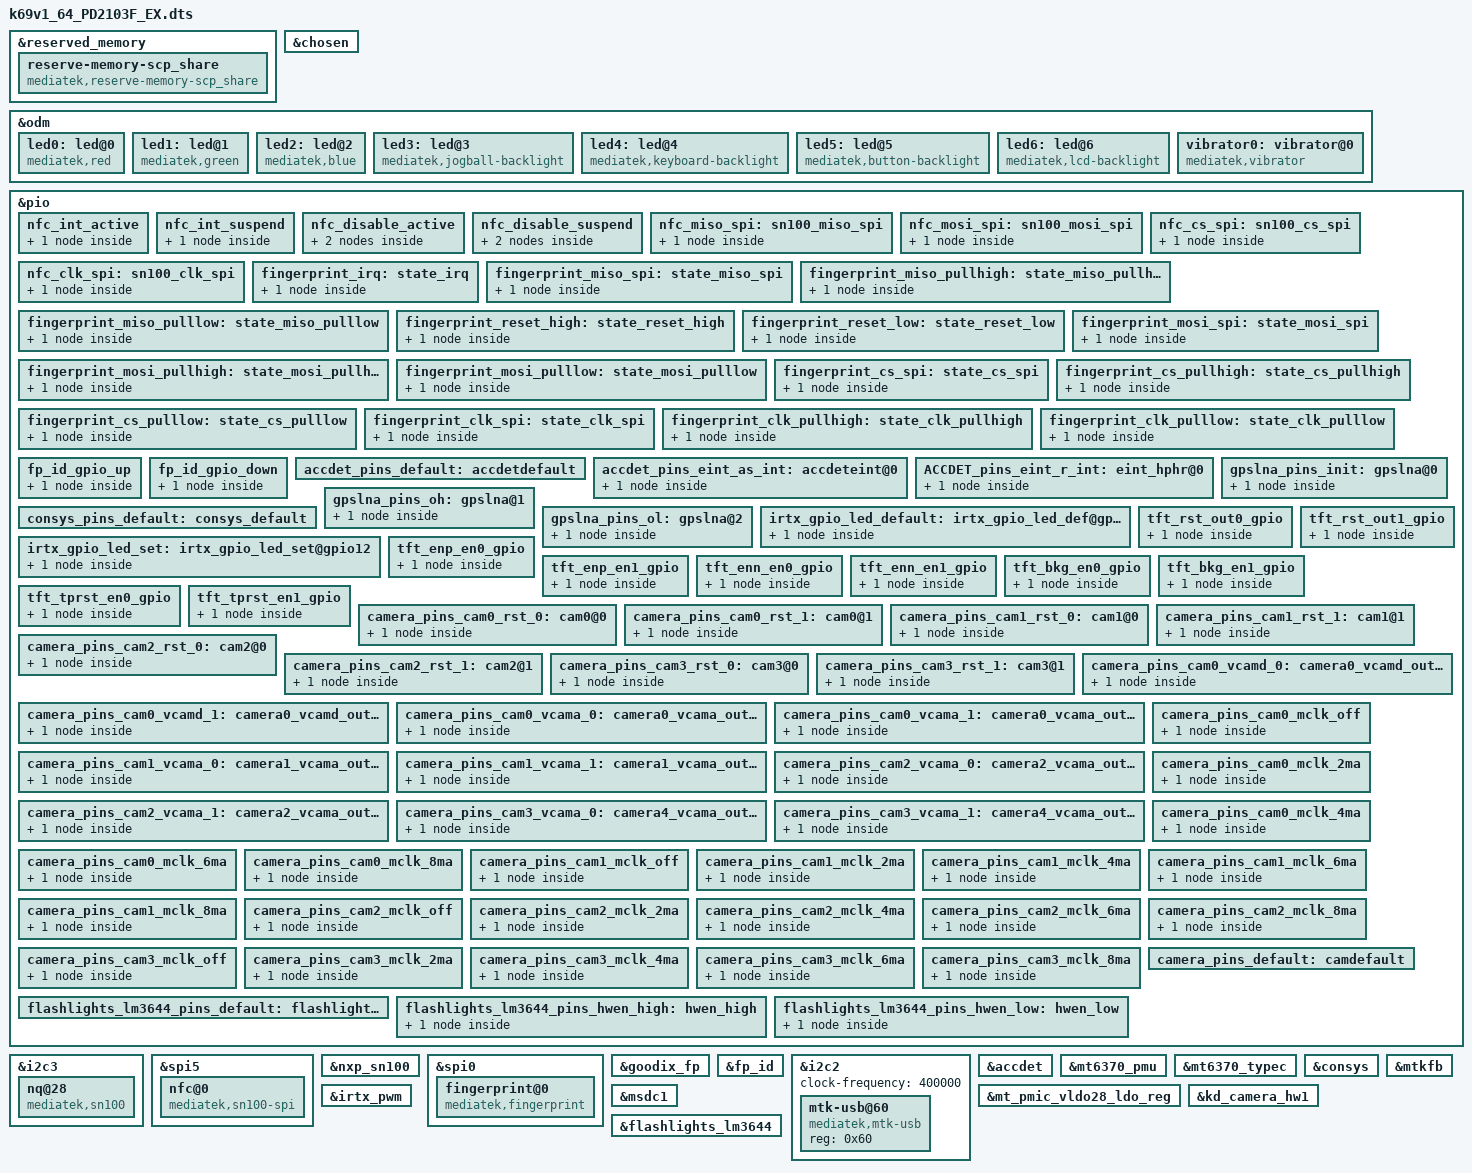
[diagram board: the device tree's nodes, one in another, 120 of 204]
/*
 * Copyright (C) 2019 MediaTek Inc.
 *
 * This program is free software; you can redistribute it and/or modify
 * it under the terms of the GNU General Public License version 2 as
 * published by the Free Software Foundation.
 *
 * This program is distributed in the hope that it will be useful,
 * but WITHOUT ANY WARRANTY; without even the implied warranty of
 * MERCHANTABILITY or FITNESS FOR A PARTICULAR PURPOSE.
 * See http://www.gnu.org/licenses/gpl-2.0.html for more details.
 */

/dts-v1/;
/plugin/;
#include <generated/autoconf.h>
#include <dt-bindings/interrupt-controller/irq.h>
#include <dt-bindings/interrupt-controller/arm-gic.h>
#include <dt-bindings/pinctrl/mt6768-pinfunc.h>

&reserved_memory {
	reserve-memory-scp_share {
		compatible = "mediatek,reserve-memory-scp_share";
		no-map;
		size = <0 0x00d00000>;
		alignment = <0 0x1000000>;
		alloc-ranges = <0 0x40000000 0 0x50000000>;
	};
};

/* chosen */
&chosen {

	atag,videolfb-fb_base_l = <0x7e605000>;
	atag,videolfb-fb_base_h = <0x0>;
	atag,videolfb-islcmfound = <1>;
	atag,videolfb-islcm_inited = <0>;
	atag,videolfb-fps= <6000>;
	atag,videolfb-vramSize= <0x017e8000>;
	atag,videolfb-lcmname=
		"hx83112b_fhdp_dsi_cmd_auo_rt5081_drv";
	default-backlight-level = <1600>;
	atag,videolfb-project-name= "pd2103";
	atag,vivo-dsi-panel-type = "tft";
	bias-ic-use-i2c = <0>;
	bl-ic-use-i2c = <0>;
};

&odm {
	led0:led@0 {
		compatible = "mediatek,red";
		led_mode = <0>;
		data = <1>;
		pwm_config = <0 0 0 0 0>;
	};
	led1:led@1 {
		compatible = "mediatek,green";
		led_mode = <0>;
		data = <1>;
		pwm_config = <0 0 0 0 0>;
	};
	led2:led@2 {
		compatible = "mediatek,blue";
		led_mode = <0>;
		data = <1>;
		pwm_config = <0 0 0 0 0>;
	};
	led3:led@3 {
		compatible = "mediatek,jogball-backlight";
		led_mode = <0>;
		data = <1>;
		pwm_config = <0 0 0 0 0>;
	};
	led4:led@4 {
		compatible = "mediatek,keyboard-backlight";
		led_mode = <0>;
		data = <1>;
		pwm_config = <0 0 0 0 0>;
	};
	led5:led@5 {
		compatible = "mediatek,button-backlight";
		led_mode = <0>;
		data = <1>;
		pwm_config = <0 0 0 0 0>;
	};
	led6:led@6 {
		compatible = "mediatek,lcd-backlight";
		led_mode = <4>;
		data = <1>;
		pwm_config = <0 3 0 0 0>;
	};
	vibrator0:vibrator@0 {
		compatible = "mediatek,vibrator";
		vib_timer = <25>;
		vib_limit = <9>;
		vib_vol= <11>;
	};
};

/* NFC GPIO standardization begin*/
&pio {
	nfc_int_active: nfc_int_active {
		pins_cmd0_dat {
			pinmux = <PINMUX_GPIO9__FUNC_GPIO9>;
			bias-pull-up;
		};
	};
	nfc_int_suspend: nfc_int_suspend {
		pins_cmd0_dat {
			pinmux = <PINMUX_GPIO9__FUNC_GPIO9>;
			bias-pull-up;
		};
	};
	nfc_disable_active: nfc_disable_active {
		pins_cmd0_dat {
			pinmux = <PINMUX_GPIO17__FUNC_GPIO17>;
			bias-pull-up;
		};
		pins_cmd1_dat {
			pinmux = <PINMUX_GPIO19__FUNC_GPIO19>;
			bias-pull-up;
		};
	};
	nfc_disable_suspend: nfc_disable_suspend {
		pins_cmd0_dat {
			pinmux = <PINMUX_GPIO17__FUNC_GPIO17>;
			bias-disable;
		};
		pins_cmd1_dat {
			pinmux = <PINMUX_GPIO19__FUNC_GPIO19>;
			bias-disable;
		};
	};

};
&i2c3 {
	status = "okay";
	#address-cells = <1>;
	#size-cells = <0>;
	clock-frequency = <400000>;
	mediatek,use-open-drain;
	nq@28 {
		compatible = "mediatek,sn100";
		reg = <0x28>;
		vivo,nfc_support = <1>;
		vivo,boardversion_shift = <7>;
		vivo,boardversion_mask = <1>;
		vivo,boardversion_num = <1>;
		vivo,boardversions = "0";
		vivo,project-name = "PD2103F_EX";
		mediatek,nq-irq = <&pio 9 0x00>;
		mediatek,nq-ven = <&pio 17 0x00>;
		mediatek,nq-firm = <&pio 19 0x00>;
		vddio-supply = <&mt_pmic_vcama1_ldo_reg>;
		//mediatek,nq-clkreq = <&pio 11 0x00>;
		interrupt-parent = <&pio>;
		interrupts = <9 0>;
		interrupt-names = "nfc_irq";
		pinctrl-names = "nfc_active", "nfc_suspend";
		pinctrl-0 = <&nfc_int_active &nfc_disable_active>;
		pinctrl-1 = <&nfc_int_suspend &nfc_disable_suspend>;
	};
};
/* NFC GPIO standardization end*/
/* NFC SPI standardization begin*/
&spi5 {
	#address-cells = <1>;
	#size-cells = <0>;
	nfc@0 {
		compatible = "mediatek,sn100-spi";
		reg = <0>;
		spi-max-frequency = <10000000>;
		status = "okay";
	};
};

&nxp_sn100 {
    status = "okay";
	pinctrl-names = "miso_spi","mosi_spi","cs_spi","clk_spi";
	pinctrl-0 = <&nfc_miso_spi>;
	pinctrl-1 = <&nfc_mosi_spi>;
	pinctrl-2 = <&nfc_cs_spi>;
	pinctrl-3 = <&nfc_clk_spi>;

};

&pio {
	nfc_miso_spi: sn100_miso_spi {
		pins_cmd_dat {
			pinmux = <PINMUX_GPIO13__FUNC_SPI5_MI>;
			drive-strength = <4>;
		};
	};
	nfc_mosi_spi: sn100_mosi_spi {
		pins_cmd_dat {
			pinmux = <PINMUX_GPIO15__FUNC_SPI5_MO>;
			drive-strength = <4>;
		};
	};
	nfc_cs_spi: sn100_cs_spi {
		pins_cmd_dat {
			pinmux = <PINMUX_GPIO14__FUNC_SPI5_CSB>;
			drive-strength = <4>;
			//bias-pull-up;
		};
	};
	nfc_clk_spi: sn100_clk_spi {
		pins_cmd_dat {
			pinmux = <PINMUX_GPIO16__FUNC_SPI5_CLK>;
			drive-strength = <4>;
		};
	};
};
/* NFC SPI standardization end*/


/* FINGERPRINT start */
&spi0 {
	#address-cells = <1>;
	#size-cells = <0>;
	fingerprint@0 {
		compatible = "mediatek,fingerprint";
		reg = <0>;
		spi-max-frequency = <8000000>;
		netlink-event = <29>;
		vfp-supply = <&mt_pmic_vcama2_ldo_reg>;
		status = "okay";
	};
};

&goodix_fp {
	pinctrl-names = "fingerprint_irq", "miso_spi", "miso_pullhigh", "miso_pulllow", "reset_high", "reset_low","mosi_spi","mosi_pullhigh","mosi_pulllow","cs_spi","cs_pullhigh","cs_pulllow","clk_spi","clk_pullhigh","clk_pulllow";
	pinctrl-0 = <&fingerprint_irq>;
	pinctrl-1 = <&fingerprint_miso_spi>;
	pinctrl-2 = <&fingerprint_miso_pullhigh>;
	pinctrl-3 = <&fingerprint_miso_pulllow>;
	pinctrl-4 = <&fingerprint_reset_high>;
	pinctrl-5 = <&fingerprint_reset_low>;
	pinctrl-6 = <&fingerprint_mosi_spi>;
	pinctrl-7 = <&fingerprint_mosi_pullhigh>;
	pinctrl-8 = <&fingerprint_mosi_pulllow>;
	pinctrl-9 = <&fingerprint_cs_spi>;
	pinctrl-10 = <&fingerprint_cs_pullhigh>;
	pinctrl-11 = <&fingerprint_cs_pulllow>;
	pinctrl-12 = <&fingerprint_clk_spi>;
	pinctrl-13 = <&fingerprint_clk_pullhigh>;
	pinctrl-14 = <&fingerprint_clk_pulllow>;
	status = "okay";
};

&pio {
	fingerprint_irq: state_irq {
		pins_cmd_dat {
			pinmux = <PINMUX_GPIO5__FUNC_GPIO5>;
			slew-rate = <0>;
			bias-disable;
		};
	};

	fingerprint_miso_spi: state_miso_spi {
		pins_cmd_dat {
			pinmux = <PINMUX_GPIO32__FUNC_SPI0_MI>;
			drive-strength = <2>;
		};
	};

	fingerprint_miso_pullhigh: state_miso_pullhigh {
		pins_cmd_dat {
			pinmux = <PINMUX_GPIO32__FUNC_GPIO32>;
			slew-rate = <1>;
			output-high;
		};
	};

	fingerprint_miso_pulllow: state_miso_pulllow {
		pins_cmd_dat {
			pinmux = <PINMUX_GPIO32__FUNC_GPIO32>;
			slew-rate = <1>;
			output-low;
		};
	};

	fingerprint_reset_high: state_reset_high {
		pins_cmd_dat {
			pinmux = <PINMUX_GPIO92__FUNC_GPIO92>;
			slew-rate = <1>;
			output-high;
		};
	};

	fingerprint_reset_low: state_reset_low {
		pins_cmd_dat {
			pinmux = <PINMUX_GPIO92__FUNC_GPIO92>;
			slew-rate = <1>;
			output-low;
		};
	};

	fingerprint_mosi_spi: state_mosi_spi {
		pins_cmd_dat {
			pinmux = <PINMUX_GPIO34__FUNC_SPI0_MO>;
			drive-strength = <2>;
		};
	};
	fingerprint_mosi_pullhigh: state_mosi_pullhigh {
		pins_cmd_dat {
			pinmux = <PINMUX_GPIO34__FUNC_GPIO34>;
			slew-rate = <1>;
			output-high;
		};
	};

	fingerprint_mosi_pulllow: state_mosi_pulllow {
		pins_cmd_dat {
			pinmux = <PINMUX_GPIO34__FUNC_GPIO34>;
			slew-rate = <1>;
			output-low;
		};
	};
	fingerprint_cs_spi: state_cs_spi {
		pins_cmd_dat {
			pinmux = <PINMUX_GPIO33__FUNC_SPI0_CSB>;
			drive-strength = <2>;
		};
	};

	fingerprint_cs_pullhigh: state_cs_pullhigh {
		pins_cmd_dat {
			pinmux = <PINMUX_GPIO33__FUNC_GPIO33>;
			slew-rate = <1>;
			output-high;
		};
	};

	fingerprint_cs_pulllow: state_cs_pulllow {
		pins_cmd_dat {
			pinmux = <PINMUX_GPIO33__FUNC_GPIO33>;
			slew-rate = <1>;
			output-low;
		};
	};

	fingerprint_clk_spi: state_clk_spi {
		pins_cmd_dat {
			pinmux = <PINMUX_GPIO35__FUNC_SPI0_CLK>;
			drive-strength = <3>;
		};
	};
	fingerprint_clk_pullhigh: state_clk_pullhigh {
		pins_cmd_dat {
			pinmux = <PINMUX_GPIO35__FUNC_GPIO35>;
			slew-rate = <1>;
			output-high;
		};
	};

	fingerprint_clk_pulllow: state_clk_pulllow {
		pins_cmd_dat {
			pinmux = <PINMUX_GPIO35__FUNC_GPIO35>;
			slew-rate = <1>;
			output-low;
		};
	};
};

&pio {
	fp_id_gpio_up: fp_id_gpio_up {
		pins_cmd_dat {
			pinmux = <PINMUX_GPIO8__FUNC_GPIO8>;
			slew-rate = <0>;
			bias-pull-up;
			input-enable;
		};
	};
	fp_id_gpio_down: fp_id_gpio_down {
		pins_cmd_dat {
			pinmux = <PINMUX_GPIO8__FUNC_GPIO8>;
			slew-rate = <0>;
			bias-pull-down;
			input-enable;
		};
	};
};
&fp_id {
	status="okay";
	vivo,project-name = "PD2066F_EX";
	/*vcc_fpc-supply = <&mt_pmic_vcama2_ldo_reg>;*/
	fp_id,gpios= <&pio 8 0>;
	pinctrl-names = "fp_gpio_pull_up",
					"fp_gpio_pull_down";
	pinctrl-0 = <&fp_id_gpio_up>;
	pinctrl-1 = <&fp_id_gpio_down>;
};
/* FINGERPRINT end */

&i2c2 {
	clock-frequency = <400000>;

	mtk-usb@60 {
		compatible = "mediatek,mtk-usb";
		reg = <0x60>;
		status = "okay";
	};
};

/* =============== accdet start (wangkairjptb add) =============== */
/* accdet start */
&accdet {
	/* accdet micbias voltage: 0x09:2.85v 0x08:2.8v 0x07:2.7v;0x05,2.5v;0x02,1.9v */
	accdet-mic-vol = <6>;
	/* accdet pwm_width, pwm_thresh, fall_delay, rise_delay
	 * debounce0, debounce1, debounce3, debounce4
	 * eint pwm_width, eint pwm_thresh
	 * eint deb(debounce0, debounce1, debounce2, debounce3), inv_debounce
	 */
	headset-mode-setting = <0x500 0x500 1 0x1f0
				0x800 0x800 0x2000 0x44>;
	accdet-plugout-debounce = <16>;
	/* 1:ACC mode, 2:low cost without in bias, 6:low cost with in bias (ACC is 1, DCC is 2) */
	accdet-mic-mode = <1>;
	/* eint_level_trigger: 8,LEVEL_LOW(DEF) ;4,LV_HIGH;others,LV_LOW */
	headset-eint-level-pol = <8>;
	/*0--MD_MAX--UP_MAX--DW_MAX*/
	headset-three-key-threshold = <0 90 210 430>;
	headset-three-key-threshold-CDD = <0 121 192 600>;
	/* 0--MD_MAX--VOICE_MAX--UP_MAX--DW_MAX vivo used */
	headset-four-key-threshold = <0 60 116 220 440>;
	pinctrl-names = "default", "state_eint_as_int","state_eint_r_as_int";
	pinctrl-0 = <&accdet_pins_default>;
	pinctrl-1 = <&accdet_pins_eint_as_int>;
	pinctrl-2 = <&ACCDET_pins_eint_r_int>;
	status = "okay";
};

&pio {
	accdet_pins_default: accdetdefault {
	};
	accdet_pins_eint_as_int: accdeteint@0 {
		pins_cmd_dat {
			pinmux = <PINMUX_GPIO7__FUNC_GPIO7>;
			slew-rate = <0>;
			bias-disable;
		};
	};
	ACCDET_pins_eint_r_int:eint_hphr@0{
		pins_cmd_dat {
			pinmux = <PINMUX_GPIO6__FUNC_GPIO6>;
			slew-rate = <0>;
			bias-disable;
		};
	};
};

/* ============ accdet end ============ */

&mt6370_pmu {
	mt6370,intr_gpio_num = <20>; /* direct defined GPIO num */
	mt6370,intr_gpio = <&pio 20 0x0>;
};
&mt6370_typec {
	mt6370pd,intr_gpio_num = <41>; /* direct defined GPIO num */
	mt6370pd,intr_gpio = <&pio 41 0x0>;
};

/* CONSYS GPIO standardization */
&pio {
	consys_pins_default: consys_default {
	};
	gpslna_pins_init: gpslna@0 {
		pins_cmd_dat {
			pinmux = <PINMUX_GPIO94__FUNC_GPIO94>;
			slew-rate = <0>;
			bias-disable;
			output-low;
		};
	};
	gpslna_pins_oh: gpslna@1 {
		pins_cmd_dat {
			pinmux = <PINMUX_GPIO94__FUNC_GPIO94>;
			slew-rate = <1>;
			output-high;
		};
	};
	gpslna_pins_ol: gpslna@2 {
		pins_cmd_dat {
			pinmux = <PINMUX_GPIO94__FUNC_GPIO94>;
			slew-rate = <1>;
			output-low;
		};
	};
};
&consys {
	pinctrl-names = "default", "gps_lna_state_init",
		"gps_lna_state_oh", "gps_lna_state_ol";
	pinctrl-0 = <&consys_pins_default>;
	pinctrl-1 = <&gpslna_pins_init>;
	pinctrl-2 = <&gpslna_pins_oh>;
	pinctrl-3 = <&gpslna_pins_ol>;
	status = "okay";
};
/* CONSYS end */

/* IRTX GPIO Start */
&irtx_pwm {
	pinctrl-names = "irtx_gpio_led_default", "irtx_gpio_led_set";
	pinctrl-0 = <&irtx_gpio_led_default>;
	pinctrl-1 = <&irtx_gpio_led_set>;
	status = "okay";
};
&pio {
	/* IRTX GPIO Settings -Start */
	/* default: GPIO0, output, high */
	irtx_gpio_led_default:irtx_gpio_led_def@gpio12 {
		pins_cmd_dat {
			pinmux = <PINMUX_GPIO12__FUNC_GPIO12>;
			slew-rate = <1>;
			bias-disable;
			output-low;
			input-schmitt-enable = <0>;
		};
	};

	irtx_gpio_led_set:irtx_gpio_led_set@gpio12 {
		pins_cmd_dat {
			pinmux = <PINMUX_GPIO12__FUNC_PWM0>;
			slew-rate = <1>;
			output-high;
		};
	};
}; /* IRTX GPIO Settings -End */

/***************for LCM GPIO config begin****************/
&mtkfb {
	pinctrl-names = 	"tft_rst_out0_gpio",
					"tft_rst_out1_gpio",
					"tft_enp_en0_gpio",
					"tft_enp_en1_gpio",
					"tft_enn_en0_gpio",
					"tft_enn_en1_gpio",
					"tft_bkg_en0_gpio",
					"tft_bkg_en1_gpio",
					"tft_tprst_en0_gpio",
					"tft_tprst_en1_gpio";

	pinctrl-0 = <&tft_rst_out0_gpio>;
	pinctrl-1 = <&tft_rst_out1_gpio>;
	pinctrl-2 = <&tft_enp_en0_gpio>;
	pinctrl-3 = <&tft_enp_en1_gpio>;
	pinctrl-4 = <&tft_enn_en0_gpio>;
	pinctrl-5 = <&tft_enn_en1_gpio>;
	pinctrl-6 = <&tft_bkg_en0_gpio>;
	pinctrl-7 = <&tft_bkg_en1_gpio>;
	pinctrl-8 = <&tft_tprst_en0_gpio>;
	pinctrl-9 = <&tft_tprst_en1_gpio>;

	status = "okay";
};
&pio {
	tft_rst_out0_gpio: tft_rst_out0_gpio {
		pins_cmd_dat {
			pinmux = <PINMUX_GPIO45__FUNC_GPIO45>;
			slew-rate = <1>;
			output-low;
		};
	};
	tft_rst_out1_gpio: tft_rst_out1_gpio {
		pins_cmd_dat {
			pinmux = <PINMUX_GPIO45__FUNC_GPIO45>;
			slew-rate = <1>;
			output-high;
		};
	};
	tft_enp_en0_gpio: tft_enp_en0_gpio {
		pins_cmd_dat {
			pinmux = <PINMUX_GPIO160__FUNC_GPIO160>;
			slew-rate = <1>;
			output-low;
		};
	};
	tft_enp_en1_gpio: tft_enp_en1_gpio {
		pins_cmd_dat {
			pinmux = <PINMUX_GPIO160__FUNC_GPIO160>;
			slew-rate = <1>;
			output-high;
		};
	};
	tft_enn_en0_gpio: tft_enn_en0_gpio {
		pins_cmd_dat {
			pinmux = <PINMUX_GPIO165__FUNC_GPIO165>;
			slew-rate = <1>;
			output-low;
		};
	};
	tft_enn_en1_gpio: tft_enn_en1_gpio {
		pins_cmd_dat {
			pinmux = <PINMUX_GPIO165__FUNC_GPIO165>;
			slew-rate = <1>;
			output-high;
		};
	};
	tft_bkg_en0_gpio: tft_bkg_en0_gpio {
		pins_cmd_dat {
			pinmux = <PINMUX_GPIO159__FUNC_GPIO159>;
			slew-rate = <1>;
			output-low;
		};
	};
	tft_bkg_en1_gpio: tft_bkg_en1_gpio {
		pins_cmd_dat {
			pinmux = <PINMUX_GPIO159__FUNC_GPIO159>;
			slew-rate = <1>;
			output-high;
		};
	};
	tft_tprst_en0_gpio: tft_tprst_en0_gpio {
		pins_cmd_dat {
			pinmux = <PINMUX_GPIO23__FUNC_GPIO23>;
			slew-rate = <1>;
			output-low;
		};
	};
	tft_tprst_en1_gpio: tft_tprst_en1_gpio {
		pins_cmd_dat {
			pinmux = <PINMUX_GPIO23__FUNC_GPIO23>;
			slew-rate = <1>;
			output-high;
		};
	};
};

&mt_pmic_vldo28_ldo_reg {
	regulator-min-microvolt = <3000000>;
	regulator-max-microvolt = <3000000>;
	regulator-always-on;
};

&msdc1 {
	fast_power_off;
	PD2103;
};

/***************for LCM GPIO config end****************/
/* CAMERA GPIO standardization */
&pio {
	camera_pins_cam0_rst_0: cam0@0 {
		pins_cmd_dat {
			pinmux = <PINMUX_GPIO102__FUNC_GPIO102>;
			slew-rate = <1>;
			output-low;
		};
	};
	camera_pins_cam0_rst_1: cam0@1 {
		pins_cmd_dat {
			pinmux = <PINMUX_GPIO102__FUNC_GPIO102>;
			slew-rate = <1>;
			output-high;
		};
	};
	camera_pins_cam1_rst_0: cam1@0 {
		pins_cmd_dat {
			pinmux = <PINMUX_GPIO101__FUNC_GPIO101>;
			slew-rate = <1>;
			output-low;
		};
	};
	camera_pins_cam1_rst_1: cam1@1 {
		pins_cmd_dat {
			pinmux = <PINMUX_GPIO101__FUNC_GPIO101>;
			slew-rate = <1>;
			output-high;
		};
	};
	camera_pins_cam2_rst_0: cam2@0 {
		pins_cmd_dat {
			pinmux = <PINMUX_GPIO109__FUNC_GPIO109>;
			slew-rate = <1>;
			output-low;
		};
	};
	camera_pins_cam2_rst_1: cam2@1 {
		pins_cmd_dat {
			pinmux = <PINMUX_GPIO109__FUNC_GPIO109>;
			slew-rate = <1>;
			output-high;
		};
	};
	camera_pins_cam3_rst_0: cam3@0 {
		pins_cmd_dat {
			pinmux = <PINMUX_GPIO112__FUNC_GPIO112>;
			slew-rate = <1>;
			output-low;
		};
	};
	camera_pins_cam3_rst_1: cam3@1 {
		pins_cmd_dat {
			pinmux = <PINMUX_GPIO112__FUNC_GPIO112>;
			slew-rate = <1>;
			output-high;
		};
	};

	camera_pins_cam0_vcamd_0: camera0_vcamd_output_low@97 {
		pins_cmd_dat {
			pinmux = <PINMUX_GPIO97__FUNC_GPIO97>;
			slew-rate = <1>;
			output-low;
		};
	};
	camera_pins_cam0_vcamd_1: camera0_vcamd_output_high@97 {
		pins_cmd_dat {
			pinmux = <PINMUX_GPIO97__FUNC_GPIO97>;
			slew-rate = <1>;
			output-high;
		};
	};

	camera_pins_cam0_vcama_0: camera0_vcama_output_low@169 {
		pins_cmd_dat {
			pinmux = <PINMUX_GPIO169__FUNC_GPIO169>;
			slew-rate = <1>;
			output-low;
		};
	};
	camera_pins_cam0_vcama_1: camera0_vcama_output_high@169 {
		pins_cmd_dat {
			pinmux = <PINMUX_GPIO169__FUNC_GPIO169>;
			slew-rate = <1>;
			output-high;
		};
	};
	camera_pins_cam1_vcama_0: camera1_vcama_output_low@169 {
		pins_cmd_dat {
			pinmux = <PINMUX_GPIO169__FUNC_GPIO169>;
			slew-rate = <1>;
			output-low;
		};
	};
	camera_pins_cam1_vcama_1: camera1_vcama_output_high@169 {
		pins_cmd_dat {
			pinmux = <PINMUX_GPIO169__FUNC_GPIO169>;
			slew-rate = <1>;
			output-high;
		};
	};
	camera_pins_cam2_vcama_0: camera2_vcama_output_low@169 {
		pins_cmd_dat {
			pinmux = <PINMUX_GPIO169__FUNC_GPIO169>;
			slew-rate = <1>;
			output-low;
		};
	};
	camera_pins_cam2_vcama_1: camera2_vcama_output_high@169 {
		pins_cmd_dat {
			pinmux = <PINMUX_GPIO169__FUNC_GPIO169>;
			slew-rate = <1>;
			output-high;
		};
	};
	camera_pins_cam3_vcama_0: camera4_vcama_output_low@169 {
		pins_cmd_dat {
			pinmux = <PINMUX_GPIO169__FUNC_GPIO169>;
			slew-rate = <1>;
			output-low;
		};
	};
	camera_pins_cam3_vcama_1: camera4_vcama_output_high@169 {
		pins_cmd_dat {
			pinmux = <PINMUX_GPIO169__FUNC_GPIO169>;
			slew-rate = <1>;
			output-high;
		};
	};
/*main power start*/


/*main power end*/

/*sub power start*/


/*sub power end*/

/*main2 power start*/

/*main2 power end*/

/*main3 power start*/

/*main3 power end*/

	camera_pins_cam0_mclk_off: camera_pins_cam0_mclk_off {
		pins_cmd_dat {
			pinmux = <PINMUX_GPIO100__FUNC_GPIO100>;
			drive-strength = <1>;
		};
	};
	camera_pins_cam0_mclk_2ma: camera_pins_cam0_mclk_2ma {
		pins_cmd_dat {
			pinmux = <PINMUX_GPIO100__FUNC_CMMCLK1>;
			drive-strength = <0>;
		};
	};
	camera_pins_cam0_mclk_4ma: camera_pins_cam0_mclk_4ma {
		pins_cmd_dat {
			pinmux = <PINMUX_GPIO100__FUNC_CMMCLK1>;
			drive-strength = <1>;
		};
	};
	camera_pins_cam0_mclk_6ma: camera_pins_cam0_mclk_6ma {
		pins_cmd_dat {
			pinmux = <PINMUX_GPIO100__FUNC_CMMCLK1>;
			drive-strength = <2>;
		};
	};
	camera_pins_cam0_mclk_8ma: camera_pins_cam0_mclk_8ma {
		pins_cmd_dat {
			pinmux = <PINMUX_GPIO100__FUNC_CMMCLK1>;
			drive-strength = <3>;
		};
	};

	camera_pins_cam1_mclk_off: camera_pins_cam1_mclk_off {
		pins_cmd_dat {
			pinmux = <PINMUX_GPIO99__FUNC_GPIO99>;
			drive-strength = <1>;
		};
	};
	camera_pins_cam1_mclk_2ma: camera_pins_cam1_mclk_2ma {
		pins_cmd_dat {
			pinmux = <PINMUX_GPIO99__FUNC_CMMCLK0>;
			drive-strength = <0>;
		};
	};
	camera_pins_cam1_mclk_4ma: camera_pins_cam1_mclk_4ma {
		pins_cmd_dat {
			pinmux = <PINMUX_GPIO99__FUNC_CMMCLK0>;
			drive-strength = <1>;
		};
	};
	camera_pins_cam1_mclk_6ma: camera_pins_cam1_mclk_6ma {
		pins_cmd_dat {
			pinmux = <PINMUX_GPIO99__FUNC_CMMCLK0>;
			drive-strength = <2>;
		};
	};
	camera_pins_cam1_mclk_8ma: camera_pins_cam1_mclk_8ma {
		pins_cmd_dat {
			pinmux = <PINMUX_GPIO99__FUNC_CMMCLK0>;
			drive-strength = <3>;
		};
	};


	camera_pins_cam2_mclk_off: camera_pins_cam2_mclk_off {
		pins_cmd_dat {
			pinmux = <PINMUX_GPIO108__FUNC_GPIO108>;
			drive-strength = <1>;
		};
	};
	camera_pins_cam2_mclk_2ma: camera_pins_cam2_mclk_2ma {
		pins_cmd_dat {
			pinmux = <PINMUX_GPIO108__FUNC_CMMCLK2>;
			drive-strength = <0>;
		};
	};
	camera_pins_cam2_mclk_4ma: camera_pins_cam2_mclk_4ma {
		pins_cmd_dat {
			pinmux = <PINMUX_GPIO108__FUNC_CMMCLK2>;
			drive-strength = <1>;
		};
	};
	camera_pins_cam2_mclk_6ma: camera_pins_cam2_mclk_6ma {
		pins_cmd_dat {
			pinmux = <PINMUX_GPIO108__FUNC_CMMCLK2>;
			drive-strength = <2>;
		};
	};
	camera_pins_cam2_mclk_8ma: camera_pins_cam2_mclk_8ma {
		pins_cmd_dat {
			pinmux = <PINMUX_GPIO108__FUNC_CMMCLK2>;
			drive-strength = <3>;
		};
	};

	camera_pins_cam3_mclk_off: camera_pins_cam3_mclk_off {
		pins_cmd_dat {
			pinmux = <PINMUX_GPIO111__FUNC_GPIO111>;
			drive-strength = <1>;
		};
	};
	camera_pins_cam3_mclk_2ma: camera_pins_cam3_mclk_2ma {
		pins_cmd_dat {
			pinmux = <PINMUX_GPIO111__FUNC_CMMCLK3>;
			drive-strength = <0>;
		};
	};
	camera_pins_cam3_mclk_4ma: camera_pins_cam3_mclk_4ma {
		pins_cmd_dat {
			pinmux = <PINMUX_GPIO111__FUNC_CMMCLK3>;
			drive-strength = <1>;
		};
	};
	camera_pins_cam3_mclk_6ma: camera_pins_cam3_mclk_6ma {
		pins_cmd_dat {
			pinmux = <PINMUX_GPIO111__FUNC_CMMCLK3>;
			drive-strength = <2>;
		};
	};
	camera_pins_cam3_mclk_8ma: camera_pins_cam3_mclk_8ma {
		pins_cmd_dat {
			pinmux = <PINMUX_GPIO111__FUNC_CMMCLK3>;
			drive-strength = <3>;
		};
	};

	camera_pins_default: camdefault {
	};
};
&kd_camera_hw1 {
	pinctrl-names = "default",
			"cam0_rst0", "cam0_rst1",
			"cam1_rst0", "cam1_rst1",
			"cam2_rst0", "cam2_rst1",
			"cam3_rst0", "cam3_rst1",
			"cam0_vcamd_off","cam0_vcamd_on",
			"cam0_vcama_off","cam0_vcama_on",
			"cam1_vcama_off","cam1_vcama_on",
			"cam2_vcama_off","cam2_vcama_on",
			"cam3_vcama_off","cam3_vcama_on",
			"cam0_mclk_off",
			"cam0_mclk_2mA", "cam0_mclk_4mA",
			"cam0_mclk_6mA", "cam0_mclk_8mA",
			"cam1_mclk_off",
			"cam1_mclk_2mA", "cam1_mclk_4mA",
			"cam1_mclk_6mA", "cam1_mclk_8mA",
			"cam2_mclk_off",
			"cam2_mclk_2mA", "cam2_mclk_4mA",
			"cam2_mclk_6mA", "cam2_mclk_8mA",
			"cam3_mclk_off",
			"cam3_mclk_2mA", "cam3_mclk_4mA",
			"cam3_mclk_6mA", "cam3_mclk_8mA";
	pinctrl-0 = <&camera_pins_default>;
	pinctrl-1 = <&camera_pins_cam0_rst_0>;
	pinctrl-2 = <&camera_pins_cam0_rst_1>;
	pinctrl-3 = <&camera_pins_cam1_rst_0>;
	pinctrl-4 = <&camera_pins_cam1_rst_1>;
	pinctrl-5 = <&camera_pins_cam2_rst_0>;
	pinctrl-6 = <&camera_pins_cam2_rst_1>;
	pinctrl-7 = <&camera_pins_cam3_rst_0>;
	pinctrl-8 = <&camera_pins_cam3_rst_1>;
	pinctrl-9 = <&camera_pins_cam0_vcamd_0>;
	pinctrl-10 = <&camera_pins_cam0_vcamd_1>;
	pinctrl-11 = <&camera_pins_cam0_vcama_0>;
	pinctrl-12 = <&camera_pins_cam0_vcama_1>;
	pinctrl-13 = <&camera_pins_cam1_vcama_0>;
	pinctrl-14 = <&camera_pins_cam1_vcama_1>;
	pinctrl-15 = <&camera_pins_cam2_vcama_0>;
	pinctrl-16 = <&camera_pins_cam2_vcama_1>;
	pinctrl-17 = <&camera_pins_cam3_vcama_0>;
	pinctrl-18 = <&camera_pins_cam3_vcama_1>;
	pinctrl-19 = <&camera_pins_cam0_mclk_off>;
	pinctrl-20 = <&camera_pins_cam0_mclk_2ma>;
	pinctrl-21 = <&camera_pins_cam0_mclk_4ma>;
	pinctrl-22 = <&camera_pins_cam0_mclk_6ma>;
	pinctrl-23 = <&camera_pins_cam0_mclk_8ma>;
	pinctrl-24 = <&camera_pins_cam1_mclk_off>;
	pinctrl-25 = <&camera_pins_cam1_mclk_2ma>;
	pinctrl-26 = <&camera_pins_cam1_mclk_4ma>;
	pinctrl-27 = <&camera_pins_cam1_mclk_6ma>;
	pinctrl-28 = <&camera_pins_cam1_mclk_8ma>;
	pinctrl-29 = <&camera_pins_cam2_mclk_off>;
	pinctrl-30 = <&camera_pins_cam2_mclk_2ma>;
	pinctrl-31 = <&camera_pins_cam2_mclk_4ma>;
	pinctrl-32 = <&camera_pins_cam2_mclk_6ma>;
	pinctrl-33 = <&camera_pins_cam2_mclk_8ma>;
	pinctrl-34 = <&camera_pins_cam3_mclk_off>;
	pinctrl-35 = <&camera_pins_cam3_mclk_2ma>;
	pinctrl-36 = <&camera_pins_cam3_mclk_4ma>;
	pinctrl-37 = <&camera_pins_cam3_mclk_6ma>;
	pinctrl-38 = <&camera_pins_cam3_mclk_8ma>;
	
	status = "okay";
};
/* CAMERA GPIO end */
/* FLASHLIGHT START*/
&pio {
	flashlights_lm3644_pins_default: flashlight_default {
	};

	flashlights_lm3644_pins_hwen_high: hwen_high {
		pins_cmd_dat {
			pinmux = <PINMUX_GPIO152__FUNC_GPIO152>;
			slew-rate = <1>;
			output-high;
		};
	};

	flashlights_lm3644_pins_hwen_low: hwen_low {
		pins_cmd_dat {
			pinmux = <PINMUX_GPIO152__FUNC_GPIO152>;
			slew-rate = <1>;
			output-low;
		};
	};
/*
	flashlights_lm3644_pins_irq: flash_irq {
		pins_cmd_dat {
			pinmux = <PINMUX_GPIO107__FUNC_GPIO107>;
			slew-rate = <0>;
			bias-disable;
		};
	};

*/
};

&flashlights_lm3644 {
	pinctrl-names = "default", "hwen_high", "hwen_low" /*,"flash_irq"*/;
	pinctrl-0 = <&flashlights_lm3644_pins_default>;
	pinctrl-1 = <&flashlights_lm3644_pins_hwen_high>;
	pinctrl-2 = <&flashlights_lm3644_pins_hwen_low>;
	/*pinctrl-3 = <&flashlights_lm3644_pins_irq>;*/
	status = "okay";
};
#include "mediatek/cust_vivo_PD2103F_EX.dtsi"
//#include "mediatek/cust_mt6768_camera.dtsi"
#include "mediatek/vivo_tp_setting/mtk-vivo-tp-PD2103F_EX.dtsi"
/*End of this file, DO NOT ADD ANYTHING HERE*/
